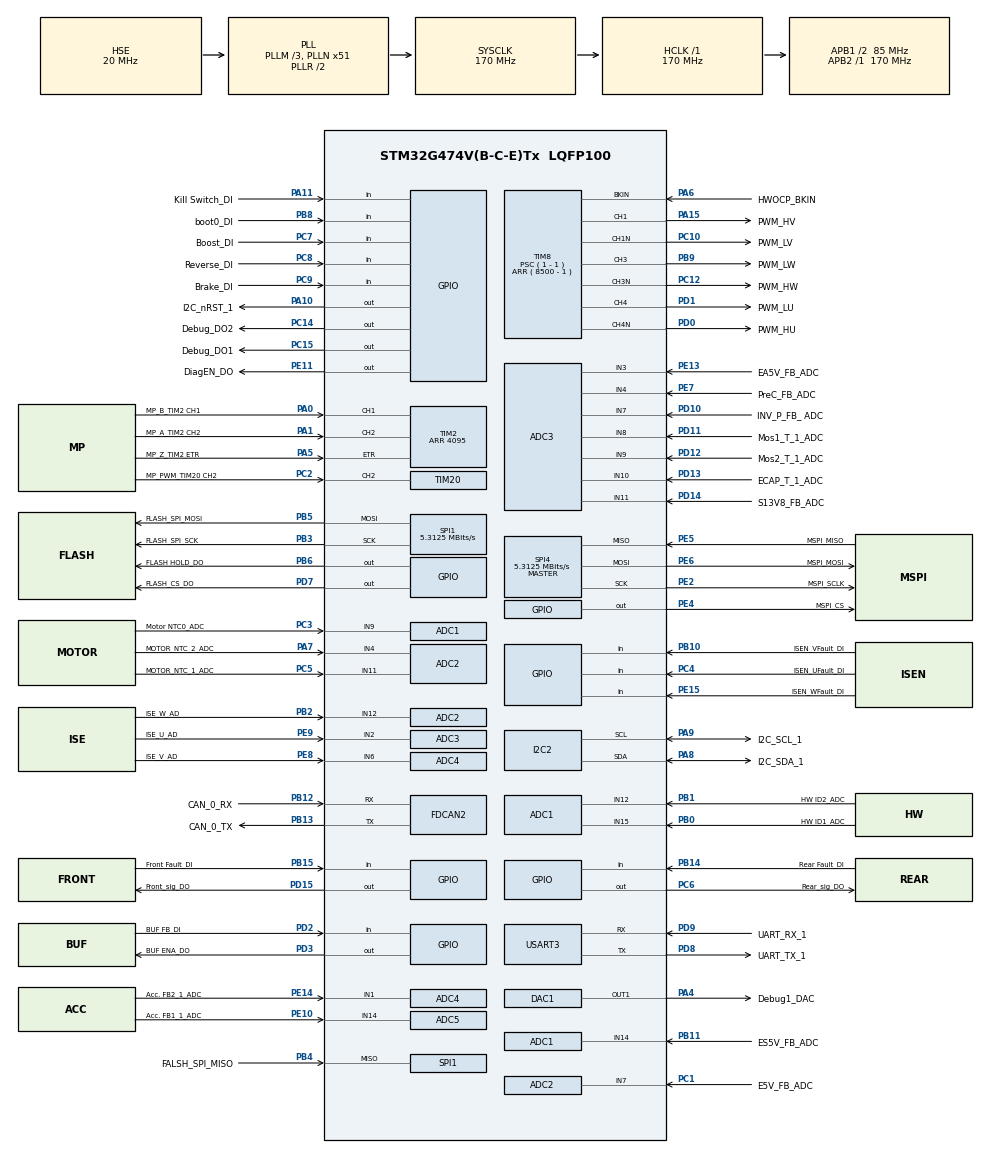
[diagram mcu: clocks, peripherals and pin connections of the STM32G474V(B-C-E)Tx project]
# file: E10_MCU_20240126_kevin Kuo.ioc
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ADC1.Channel-1\#ChannelRegularConversion=ADC_CHANNEL_9
ADC1.Channel-2\#ChannelRegularConversion=ADC_CHANNEL_14
ADC1.Channel-3\#ChannelRegularConversion=ADC_CHANNEL_15
ADC1.Channel-4\#ChannelRegularConversion=ADC_CHANNEL_12
ADC1.ClockPrescaler=ADC_CLOCK_ASYNC_DIV4
ADC1.DMAContinuousRequests=ENABLE
ADC1.EOCSelection=ADC_EOC_SEQ_CONV
ADC1.ExternalTrigConv=ADC_EXTERNALTRIG_T6_TRGO
ADC1.NbrOfConversion=4
ADC1.NbrOfConversionFlag=1
ADC1.OffsetNumber-1\#ChannelRegularConversion=ADC_OFFSET_NONE
ADC1.OffsetNumber-2\#ChannelRegularConversion=ADC_OFFSET_NONE
ADC1.OffsetNumber-3\#ChannelRegularConversion=ADC_OFFSET_NONE
ADC1.OffsetNumber-4\#ChannelRegularConversion=ADC_OFFSET_NONE
ADC1.Rank-1\#ChannelRegularConversion=1
ADC1.Rank-2\#ChannelRegularConversion=2
ADC1.Rank-3\#ChannelRegularConversion=3
ADC1.Rank-4\#ChannelRegularConversion=4
ADC1.SamplingTime-1\#ChannelRegularConversion=ADC_SAMPLETIME_47CYCLES_5
ADC1.SamplingTime-2\#ChannelRegularConversion=ADC_SAMPLETIME_47CYCLES_5
ADC1.SamplingTime-3\#ChannelRegularConversion=ADC_SAMPLETIME_47CYCLES_5
ADC1.SamplingTime-4\#ChannelRegularConversion=ADC_SAMPLETIME_47CYCLES_5
ADC1.master=1
ADC2.Channel-0\#ChannelRegularConversion=ADC_CHANNEL_7
ADC2.Channel-3\#ChannelRegularConversion=ADC_CHANNEL_11
ADC2.Channel-4\#ChannelRegularConversion=ADC_CHANNEL_4
ADC2.ClockPrescaler=ADC_CLOCK_ASYNC_DIV4
ADC2.DMAContinuousRequests=ENABLE
ADC2.EOCSelection=ADC_EOC_SEQ_CONV
ADC2.EnableInjectedConversion=ENABLE
ADC2.ExternalTrigConv=ADC_EXTERNALTRIG_T6_TRGO
ADC2.ExternalTrigInjecConv=ADC_EXTERNALTRIGINJEC_T8_TRGO
ADC2.InjNumberOfConversion=1
ADC2.InjectedChannel-2\#ChannelInjectedConversion=ADC_CHANNEL_12
ADC2.InjectedOffsetNumber-2\#ChannelInjectedConversion=ADC_OFFSET_NONE
ADC2.InjectedRank-2\#ChannelInjectedConversion=1
ADC2.InjectedSamplingTime-2\#ChannelInjectedConversion=ADC_SAMPLETIME_12CYCLES_5
ADC2.NbrOfConversion=3
ADC2.NbrOfConversionFlag=1
ADC2.OffsetNumber-0\#ChannelRegularConversion=ADC_OFFSET_NONE
ADC2.OffsetNumber-3\#ChannelRegularConversion=ADC_OFFSET_NONE
ADC2.OffsetNumber-4\#ChannelRegularConversion=ADC_OFFSET_NONE
ADC2.Rank-0\#ChannelRegularConversion=1
ADC2.Rank-3\#ChannelRegularConversion=2
ADC2.Rank-4\#ChannelRegularConversion=3
ADC2.SamplingTime-0\#ChannelRegularConversion=ADC_SAMPLETIME_92CYCLES_5
ADC2.SamplingTime-3\#ChannelRegularConversion=ADC_SAMPLETIME_92CYCLES_5
ADC2.SamplingTime-4\#ChannelRegularConversion=ADC_SAMPLETIME_92CYCLES_5
ADC3.Channel-0\#ChannelRegularConversion=ADC_CHANNEL_10
ADC3.Channel-1\#ChannelRegularConversion=ADC_CHANNEL_8
ADC3.Channel-2\#ChannelRegularConversion=ADC_CHANNEL_9
ADC3.Channel-3\#ChannelRegularConversion=ADC_CHANNEL_4
ADC3.Channel-4\#ChannelRegularConversion=ADC_CHANNEL_11
ADC3.Channel-5\#ChannelRegularConversion=ADC_CHANNEL_3
ADC3.ClockPrescaler=ADC_CLOCK_ASYNC_DIV4
ADC3.DMAContinuousRequests=ENABLE
ADC3.EOCSelection=ADC_EOC_SEQ_CONV
ADC3.EnableInjectedConversion=ENABLE
ADC3.ExternalTrigConv=ADC_EXTERNALTRIG_T6_TRGO
ADC3.ExternalTrigInjecConv=ADC_EXTERNALTRIGINJEC_T8_TRGO
ADC3.InjNumberOfConversion=2
ADC3.InjectedChannel-6\#ChannelInjectedConversion=ADC_CHANNEL_2
ADC3.InjectedChannel-7\#ChannelInjectedConversion=ADC_CHANNEL_7
ADC3.InjectedOffsetNumber-6\#ChannelInjectedConversion=ADC_OFFSET_NONE
ADC3.InjectedOffsetNumber-7\#ChannelInjectedConversion=ADC_OFFSET_NONE
ADC3.InjectedRank-6\#ChannelInjectedConversion=1
ADC3.InjectedRank-7\#ChannelInjectedConversion=2
ADC3.InjectedSamplingTime-6\#ChannelInjectedConversion=ADC_SAMPLETIME_12CYCLES_5
ADC3.InjectedSamplingTime-7\#ChannelInjectedConversion=ADC_SAMPLETIME_12CYCLES_5
ADC3.NbrOfConversion=6
ADC3.NbrOfConversionFlag=1
ADC3.OffsetNumber-0\#ChannelRegularConversion=ADC_OFFSET_NONE
ADC3.OffsetNumber-1\#ChannelRegularConversion=ADC_OFFSET_NONE
ADC3.OffsetNumber-2\#ChannelRegularConversion=ADC_OFFSET_NONE
ADC3.OffsetNumber-3\#ChannelRegularConversion=ADC_OFFSET_NONE
ADC3.OffsetNumber-4\#ChannelRegularConversion=ADC_OFFSET_NONE
ADC3.OffsetNumber-5\#ChannelRegularConversion=ADC_OFFSET_NONE
ADC3.Rank-0\#ChannelRegularConversion=1
ADC3.Rank-1\#ChannelRegularConversion=2
ADC3.Rank-2\#ChannelRegularConversion=3
ADC3.Rank-3\#ChannelRegularConversion=4
ADC3.Rank-4\#ChannelRegularConversion=5
ADC3.Rank-5\#ChannelRegularConversion=6
ADC3.Rank1_Channel=ADC_CHANNEL_2
ADC3.Rank2_Channel=ADC_CHANNEL_7
ADC3.SamplingTime-0\#ChannelRegularConversion=ADC_SAMPLETIME_47CYCLES_5
ADC3.SamplingTime-1\#ChannelRegularConversion=ADC_SAMPLETIME_47CYCLES_5
ADC3.SamplingTime-2\#ChannelRegularConversion=ADC_SAMPLETIME_47CYCLES_5
ADC3.SamplingTime-3\#ChannelRegularConversion=ADC_SAMPLETIME_47CYCLES_5
ADC3.SamplingTime-4\#ChannelRegularConversion=ADC_SAMPLETIME_47CYCLES_5
ADC3.SamplingTime-5\#ChannelRegularConversion=ADC_SAMPLETIME_47CYCLES_5
ADC3.master=1
ADC4.Channel-0\#ChannelRegularConversion=ADC_CHANNEL_1
ADC4.ClockPrescaler=ADC_CLOCK_ASYNC_DIV4
ADC4.DMAContinuousRequests=ENABLE
ADC4.EOCSelection=ADC_EOC_SEQ_CONV
ADC4.EnableInjectedConversion=ENABLE
ADC4.ExternalTrigConv=ADC_EXTERNALTRIG_T6_TRGO
ADC4.ExternalTrigInjecConv=ADC_EXTERNALTRIGINJEC_T8_TRGO
ADC4.InjNumberOfConversion=1
ADC4.InjectedChannel-2\#ChannelInjectedConversion=ADC_CHANNEL_6
ADC4.InjectedOffsetNumber-2\#ChannelInjectedConversion=ADC_OFFSET_NONE
ADC4.InjectedRank-2\#ChannelInjectedConversion=1
ADC4.InjectedSamplingTime-2\#ChannelInjectedConversion=ADC_SAMPLETIME_12CYCLES_5
ADC4.NbrOfConversion=1
ADC4.NbrOfConversionFlag=1
ADC4.OffsetNumber-0\#ChannelRegularConversion=ADC_OFFSET_NONE
ADC4.Rank-0\#ChannelRegularConversion=1
ADC4.Rank1_Channel=ADC_CHANNEL_6
ADC4.SamplingTime-0\#ChannelRegularConversion=ADC_SAMPLETIME_247CYCLES_5
ADC5.Channel-0\#ChannelRegularConversion=ADC_CHANNEL_14
ADC5.ClockPrescaler=ADC_CLOCK_ASYNC_DIV4
ADC5.DMAContinuousRequests=ENABLE
ADC5.EOCSelection=ADC_EOC_SEQ_CONV
ADC5.ExternalTrigConv=ADC_EXTERNALTRIG_T6_TRGO
ADC5.NbrOfConversionFlag=1
ADC5.OffsetNumber-0\#ChannelRegularConversion=ADC_OFFSET_NONE
ADC5.Rank-0\#ChannelRegularConversion=1
ADC5.SamplingTime-0\#ChannelRegularConversion=ADC_SAMPLETIME_247CYCLES_5
CRC.CRCLength=CRC_POLYLENGTH_16B
CRC.DefaultInitValueUse=DEFAULT_INIT_VALUE_DISABLE
CRC.DefaultPolynomialUse=DEFAULT_POLYNOMIAL_DISABLE
CRC.GeneratingPolynomial=X12+X5+X0
CRC.InitValue=0x0000
CRC.InputDataInversionMode=CRC_INPUTDATA_INVERSION_BYTE
CRC.OutputDataInversionMode=CRC_OUTPUTDATA_INVERSION_ENABLE
DAC1.DAC_SampleAndHold-DAC_OUT1=DAC_SAMPLEANDHOLD_DISABLE
Dma.ADC1.4.Direction=DMA_PERIPH_TO_MEMORY
Dma.ADC1.4.EventEnable=DISABLE
Dma.ADC1.4.Instance=DMA1_Channel1
Dma.ADC1.4.MemDataAlignment=DMA_MDATAALIGN_HALFWORD
Dma.ADC1.4.MemInc=DMA_MINC_ENABLE
Dma.ADC1.4.Mode=DMA_CIRCULAR
Dma.ADC1.4.PeriphDataAlignment=DMA_PDATAALIGN_HALFWORD
Dma.ADC1.4.PeriphInc=DMA_PINC_DISABLE
Dma.ADC1.4.Polarity=HAL_DMAMUX_REQ_GEN_RISING
Dma.ADC1.4.Priority=DMA_PRIORITY_LOW
Dma.ADC1.4.RequestNumber=1
Dma.ADC1.4.SignalID=NONE
Dma.ADC1.4.SyncEnable=DISABLE
Dma.ADC1.4.SyncPolarity=HAL_DMAMUX_SYNC_NO_EVENT
Dma.ADC1.4.SyncRequestNumber=1
Dma.ADC1.4.SyncSignalID=NONE
Dma.ADC2.3.Direction=DMA_PERIPH_TO_MEMORY
Dma.ADC2.3.EventEnable=DISABLE
Dma.ADC2.3.Instance=DMA1_Channel2
Dma.ADC2.3.MemDataAlignment=DMA_MDATAALIGN_HALFWORD
Dma.ADC2.3.MemInc=DMA_MINC_ENABLE
Dma.ADC2.3.Mode=DMA_CIRCULAR
Dma.ADC2.3.PeriphDataAlignment=DMA_PDATAALIGN_HALFWORD
Dma.ADC2.3.PeriphInc=DMA_PINC_DISABLE
Dma.ADC2.3.Polarity=HAL_DMAMUX_REQ_GEN_RISING
Dma.ADC2.3.Priority=DMA_PRIORITY_MEDIUM
Dma.ADC2.3.RequestNumber=1
Dma.ADC2.3.SignalID=NONE
Dma.ADC2.3.SyncEnable=DISABLE
Dma.ADC2.3.SyncPolarity=HAL_DMAMUX_SYNC_NO_EVENT
Dma.ADC2.3.SyncRequestNumber=1
Dma.ADC2.3.SyncSignalID=NONE
Dma.ADC3.2.Direction=DMA_PERIPH_TO_MEMORY
Dma.ADC3.2.EventEnable=DISABLE
Dma.ADC3.2.Instance=DMA1_Channel3
Dma.ADC3.2.MemDataAlignment=DMA_MDATAALIGN_HALFWORD
Dma.ADC3.2.MemInc=DMA_MINC_ENABLE
Dma.ADC3.2.Mode=DMA_CIRCULAR
Dma.ADC3.2.PeriphDataAlignment=DMA_PDATAALIGN_HALFWORD
Dma.ADC3.2.PeriphInc=DMA_PINC_DISABLE
Dma.ADC3.2.Polarity=HAL_DMAMUX_REQ_GEN_RISING
Dma.ADC3.2.Priority=DMA_PRIORITY_MEDIUM
Dma.ADC3.2.RequestNumber=1
Dma.ADC3.2.SignalID=NONE
Dma.ADC3.2.SyncEnable=DISABLE
Dma.ADC3.2.SyncPolarity=HAL_DMAMUX_SYNC_NO_EVENT
Dma.ADC3.2.SyncRequestNumber=1
Dma.ADC3.2.SyncSignalID=NONE
Dma.ADC4.1.Direction=DMA_PERIPH_TO_MEMORY
Dma.ADC4.1.EventEnable=DISABLE
Dma.ADC4.1.Instance=DMA1_Channel4
Dma.ADC4.1.MemDataAlignment=DMA_MDATAALIGN_HALFWORD
Dma.ADC4.1.MemInc=DMA_MINC_ENABLE
Dma.ADC4.1.Mode=DMA_CIRCULAR
Dma.ADC4.1.PeriphDataAlignment=DMA_PDATAALIGN_HALFWORD
Dma.ADC4.1.PeriphInc=DMA_PINC_DISABLE
Dma.ADC4.1.Polarity=HAL_DMAMUX_REQ_GEN_RISING
Dma.ADC4.1.Priority=DMA_PRIORITY_HIGH
Dma.ADC4.1.RequestNumber=1
Dma.ADC4.1.SignalID=NONE
Dma.ADC4.1.SyncEnable=DISABLE
Dma.ADC4.1.SyncPolarity=HAL_DMAMUX_SYNC_NO_EVENT
Dma.ADC4.1.SyncRequestNumber=1
Dma.ADC4.1.SyncSignalID=NONE
Dma.ADC5.0.Direction=DMA_PERIPH_TO_MEMORY
Dma.ADC5.0.EventEnable=DISABLE
Dma.ADC5.0.Instance=DMA1_Channel5
Dma.ADC5.0.MemDataAlignment=DMA_MDATAALIGN_HALFWORD
Dma.ADC5.0.MemInc=DMA_MINC_ENABLE
Dma.ADC5.0.Mode=DMA_CIRCULAR
Dma.ADC5.0.PeriphDataAlignment=DMA_PDATAALIGN_HALFWORD
Dma.ADC5.0.PeriphInc=DMA_PINC_DISABLE
Dma.ADC5.0.Polarity=HAL_DMAMUX_REQ_GEN_RISING
Dma.ADC5.0.Priority=DMA_PRIORITY_HIGH
Dma.ADC5.0.RequestNumber=1
Dma.ADC5.0.SignalID=NONE
Dma.ADC5.0.SyncEnable=DISABLE
Dma.ADC5.0.SyncPolarity=HAL_DMAMUX_SYNC_NO_EVENT
Dma.ADC5.0.SyncRequestNumber=1
Dma.ADC5.0.SyncSignalID=NONE
Dma.Request0=ADC5
Dma.Request1=ADC4
Dma.Request2=ADC3
Dma.Request3=ADC2
Dma.Request4=ADC1
FDCAN2.CalculateBaudRateNominal=499999
FDCAN2.CalculateTimeBitNominal=2000
FDCAN2.CalculateTimeQuantumNominal=58.82352941176471
FDCAN2.DataPrescaler=5
FDCAN2.DataSyncJumpWidth=6
FDCAN2.DataTimeSeg1=25
FDCAN2.DataTimeSeg2=8
FDCAN2.ExtFiltersNbr=4
FDCAN2.NominalPrescaler=5
FDCAN2.NominalSyncJumpWidth=6
FDCAN2.NominalTimeSeg1=25
FDCAN2.NominalTimeSeg2=8
FDCAN2.StdFiltersNbr=4
FDCAN2.TransmitPause=ENABLE
I2C2.CustomTiming=Disabled
I2C2.I2C_Coeff_DF=1
I2C2.I2C_Fall_Time=100
I2C2.I2C_Rise_Time=100
I2C2.Timing=0x20916FA0
Mcu.Family=STM32G4
Mcu.Name=STM32G474V(B-C-E)Tx
Mcu.Package=LQFP100
NVIC.ADC1_2_IRQn=true\:2\:0\:true\:false\:true\:true\:true\:true
NVIC.ADC3_IRQn=true\:2\:0\:true\:false\:true\:true\:true\:true
NVIC.ADC4_IRQn=true\:2\:0\:true\:false\:true\:true\:true\:true
NVIC.DMA1_Channel1_IRQn=true\:4\:0\:true\:false\:true\:false\:true\:true
NVIC.DMA1_Channel2_IRQn=true\:4\:0\:true\:false\:true\:false\:true\:true
NVIC.DMA1_Channel3_IRQn=true\:4\:0\:true\:false\:true\:false\:true\:true
NVIC.DMA1_Channel4_IRQn=true\:4\:0\:true\:false\:true\:false\:true\:true
NVIC.DMA1_Channel5_IRQn=true\:4\:0\:true\:false\:true\:false\:true\:true
NVIC.FDCAN2_IT0_IRQn=true\:8\:0\:true\:false\:true\:true\:true\:true
NVIC.FDCAN2_IT1_IRQn=true\:8\:0\:true\:false\:true\:true\:true\:true
NVIC.PriorityGroup=NVIC_PRIORITYGROUP_4
NVIC.TIM20_CC_IRQn=true\:0\:0\:false\:false\:true\:true\:true\:true
NVIC.TIM3_IRQn=true\:10\:0\:true\:false\:true\:true\:true\:true
NVIC.TIM7_DAC_IRQn=true\:6\:0\:true\:false\:true\:true\:true\:true
NVIC.TIM8_BRK_IRQn=true\:0\:0\:false\:false\:true\:true\:true\:true
NVIC.TIM8_UP_IRQn=true\:1\:0\:true\:false\:true\:true\:true\:true
PA0.GPIO_Label=MP_B_TIM2 CH1
PA0.Signal=S_TIM2_CH1
PA1.GPIO_Label=MP_A_TIM2 CH2
PA1.Signal=S_TIM2_CH2
PA10.GPIO_Label=I2C_nRST_1
PA10.Signal=GPIO_Output
PA11.GPIO_Label=Kill Switch_DI
PA11.Signal=GPIO_Input
PA13.Mode=Serial_Wire
PA13.Signal=SYS_JTMS-SWDIO
PA14.Mode=Serial_Wire
PA14.Signal=SYS_JTCK-SWCLK
PA15.GPIO_Label=PWM_HV
PA15.Signal=S_TIM8_CH1
PA4.GPIO_Label=Debug1_DAC
PA4.Signal=COMP_DAC11_group
PA5.GPIO_Label=MP_Z_TIM2 ETR
PA5.Signal=S_TIM2_ETR
PA6.GPIO_Label=HWOCP_BKIN
PA6.Mode=Activate-Break-Input
PA6.Signal=TIM8_BKIN
PA7.GPIO_Label=MOTOR_NTC_2_ADC
PA7.Mode=IN4-Single-Ended
PA7.Signal=ADC2_IN4
PA8.GPIO_Label=I2C_SDA_1
PA8.Mode=I2C
PA8.Signal=I2C2_SDA
PA9.GPIO_Label=I2C_SCL_1
PA9.Mode=I2C
PA9.Signal=I2C2_SCL
PB0.GPIO_Label=HW ID1_ADC
PB0.Mode=IN15-Single-Ended
PB0.Signal=ADC1_IN15
PB1.GPIO_Label=HW ID2_ADC
PB1.Mode=IN12-Single-Ended
PB1.Signal=ADC1_IN12
PB10.GPIO_Label=ISEN_VFault_DI
PB10.Signal=GPIO_Input
PB11.GPIO_Label=ES5V_FB_ADC
PB11.Mode=IN14-Single-Ended
PB11.Signal=ADC1_IN14
PB12.GPIO_Label=CAN_0_RX
PB12.Mode=FDCAN_Activate
PB12.Signal=FDCAN2_RX
PB13.GPIO_Label=CAN_0_TX
PB13.Mode=FDCAN_Activate
PB13.Signal=FDCAN2_TX
PB14.GPIO_Label=Rear Fault_DI
PB14.Signal=GPIO_Input
PB15.GPIO_Label=Front Fault_DI
PB15.Signal=GPIO_Input
PB2.GPIO_Label=ISE_W_AD
PB2.Mode=IN12-Single-Ended
PB2.Signal=ADC2_IN12
PB3.GPIO_Label=FLASH_SPI_SCK
PB3.Mode=Full_Duplex_Master
PB3.Signal=SPI1_SCK
PB4.GPIO_Label=FALSH_SPI_MISO
PB4.Mode=Full_Duplex_Master
PB4.Signal=SPI1_MISO
PB5.GPIO_Label=FLASH_SPI_MOSI
PB5.Mode=Full_Duplex_Master
PB5.Signal=SPI1_MOSI
PB6.GPIO_Label=FLASH HOLD_DO
PB6.Signal=GPIO_Output
PB8-BOOT0.GPIO_Label=boot0_DI
PB8-BOOT0.Signal=GPIO_Input
PB9.GPIO_Label=PWM_LW
PB9.Signal=S_TIM8_CH3
PC1.GPIO_Label=E5V_FB_ADC
PC1.Mode=IN7-Single-Ended
PC1.Signal=ADC2_IN7
PC10.GPIO_Label=PWM_LV
PC10.Mode=PWM Generation1 CH1 CH1N
PC10.Signal=TIM8_CH1N
PC12.GPIO_Label=PWM_HW
PC12.Mode=PWM Generation3 CH3 CH3N
PC12.Signal=TIM8_CH3N
PC14-OSC32_IN.GPIO_Label=Debug_DO2
PC14-OSC32_IN.Signal=GPIO_Output
PC15-OSC32_OUT.GPIO_Label=Debug_DO1
PC15-OSC32_OUT.Signal=GPIO_Output
PC2.GPIO_Label=MP_PWM_TIM20 CH2
PC2.Signal=S_TIM20_CH2
PC3.GPIO_Label=Motor NTC0_ADC
PC3.Mode=IN9-Single-Ended
PC3.Signal=ADC1_IN9
PC4.GPIO_Label=ISEN_UFault_DI
PC4.Signal=GPIO_Input
PC5.GPIO_Label=MOTOR_NTC_1_ADC
PC5.Mode=IN11-Single-Ended
PC5.Signal=ADC2_IN11
PC6.GPIO_Label=Rear_sig_DO
PC6.Signal=GPIO_Output
PC7.GPIO_Label=Boost_DI
PC7.Signal=GPIO_Input
PC8.GPIO_Label=Reverse_DI
PC8.Signal=GPIO_Input
PC9.GPIO_Label=Brake_DI
PC9.Signal=GPIO_Input
PD0.GPIO_Label=PWM_HU
PD0.Mode=PWM Generation4 CH4 CH4N
PD0.Signal=TIM8_CH4N
PD1.GPIO_Label=PWM_LU
PD1.Signal=S_TIM8_CH4
PD10.GPIO_Label=INV_P_FB_ ADC
PD10.Mode=IN7-Single-Ended
PD10.Signal=ADC3_IN7
PD11.GPIO_Label=Mos1_T_1_ADC
PD11.Mode=IN8-Single-Ended
PD11.Signal=ADC3_IN8
PD12.GPIO_Label=Mos2_T_1_ADC
PD12.Mode=IN9-Single-Ended
PD12.Signal=ADC3_IN9
PD13.GPIO_Label=ECAP_T_1_ADC
PD13.Mode=IN10-Single-Ended
PD13.Signal=ADC3_IN10
PD14.GPIO_Label=S13V8_FB_ADC
PD14.Mode=IN11-Single-Ended
PD14.Signal=ADC3_IN11
PD15.GPIO_Label=Front_sig_DO
PD15.Signal=GPIO_Output
PD2.GPIO_Label=BUF FB_DI
PD2.Signal=GPIO_Input
PD3.GPIO_Label=BUF ENA_DO
PD3.PinState=GPIO_PIN_SET
PD3.Signal=GPIO_Output
PD7.GPIO_Label=FLASH_CS_DO
PD7.Signal=GPIO_Output
PD8.GPIO_Label=UART_TX_1
PD8.Mode=Asynchronous
PD8.Signal=USART3_TX
PD9.GPIO_Label=UART_RX_1
PD9.Mode=Asynchronous
PD9.Signal=USART3_RX
PE10.GPIO_Label=Acc. FB1_1_ADC
PE10.Mode=IN14-Single-Ended
PE10.Signal=ADC5_IN14
PE11.GPIO_Label=DiagEN_DO
PE11.Signal=GPIO_Output
PE13.GPIO_Label=EA5V_FB_ADC
PE13.Mode=IN3-Single-Ended
PE13.Signal=ADC3_IN3
PE14.GPIO_Label=Acc. FB2_1_ADC
PE14.Mode=IN1-Single-Ended
PE14.Signal=ADC4_IN1
PE15.GPIO_Label=ISEN_WFault_DI
PE15.Signal=GPIO_Input
PE2.GPIO_Label=MSPI_SCLK
PE2.Mode=Full_Duplex_Master
PE2.Signal=SPI4_SCK
PE4.GPIO_Label=MSPI_CS
PE4.Signal=GPIO_Output
PE5.GPIO_Label=MSPI_MISO
PE5.Mode=Full_Duplex_Master
PE5.Signal=SPI4_MISO
PE6.GPIO_Label=MSPI_MOSI
PE6.Mode=Full_Duplex_Master
PE6.Signal=SPI4_MOSI
PE7.GPIO_Label=PreC_FB_ADC
PE7.Mode=IN4-Single-Ended
PE7.Signal=ADC3_IN4
PE8.GPIO_Label=ISE_V_AD
PE8.Mode=IN6-Single-Ended
PE8.Signal=ADC4_IN6
PE9.GPIO_Label=ISE_U_AD
PE9.Mode=IN2-Single-Ended
PE9.Signal=ADC3_IN2
PF0-OSC_IN.Mode=HSE-External-Oscillator
PF0-OSC_IN.Signal=RCC_OSC_IN
PF1-OSC_OUT.Mode=HSE-External-Oscillator
PF1-OSC_OUT.Signal=RCC_OSC_OUT
ProjectManager.HeapSize=0x100
ProjectManager.StackSize=0x400
ProjectManager.TargetToolchain=STM32CubeIDE
RCC.ADC12Freq_Value=170000000
RCC.ADC345Freq_Value=170000000
RCC.AHBFreq_Value=170000000
RCC.APB1CLKDivider=RCC_HCLK_DIV2
RCC.APB1Freq_Value=85000000
RCC.APB1TimFreq_Value=170000000
RCC.APB2Freq_Value=170000000
RCC.APB2TimFreq_Value=170000000
RCC.CortexFreq_Value=170000000
RCC.EXTERNAL_CLOCK_VALUE=12288000
RCC.HCLKFreq_Value=170000000
RCC.HSE_VALUE=20000000
RCC.HSI48_VALUE=48000000
RCC.HSI_VALUE=16000000
RCC.LSE_VALUE=32768
RCC.PLLM=RCC_PLLM_DIV3
RCC.PLLN=51
RCC.PLLSourceVirtual=RCC_PLLSOURCE_HSE
RCC.PWR_Regulator_Voltage_Scale=PWR_REGULATOR_VOLTAGE_SCALE1_BOOST
RCC.SYSCLKFreq_VALUE=170000000
RCC.SYSCLKSource=RCC_SYSCLKSOURCE_PLLCLK
RCC.USBFreq_Value=170000000
RCC.VCOOutputFreq_Value=340000000
SH.COMP_DAC11_group.0=DAC1_OUT1,DAC_OUT1
SH.S_TIM20_CH2.0=TIM20_CH2,PWM_Input_2
SH.S_TIM2_CH1.0=TIM2_CH1,Encoder_Interface_w_index
SH.S_TIM2_CH2.0=TIM2_CH2,Encoder_Interface_w_index
SH.S_TIM2_ETR.0=TIM2_ETR,Encoder_Interface_w_index
SH.S_TIM8_CH1.0=TIM8_CH1,PWM Generation1 CH1 CH1N
SH.S_TIM8_CH3.0=TIM8_CH3,PWM Generation3 CH3 CH3N
SH.S_TIM8_CH4.0=TIM8_CH4,PWM Generation4 CH4 CH4N
SPI1.BaudRatePrescaler=SPI_BAUDRATEPRESCALER_32
SPI1.CalculateBaudRate=5.3125 MBits/s
SPI1.DataSize=SPI_DATASIZE_8BIT
SPI1.Direction=SPI_DIRECTION_2LINES
SPI1.Mode=SPI_MODE_MASTER
SPI1.NSSPMode=SPI_NSS_PULSE_DISABLE
SPI1.VirtualType=VM_MASTER
SPI4.BaudRatePrescaler=SPI_BAUDRATEPRESCALER_32
SPI4.CLKPhase=SPI_PHASE_2EDGE
SPI4.CLKPolarity=SPI_POLARITY_HIGH
SPI4.CalculateBaudRate=5.3125 MBits/s
SPI4.DataSize=SPI_DATASIZE_16BIT
SPI4.Direction=SPI_DIRECTION_2LINES
SPI4.Mode=SPI_MODE_MASTER
SPI4.VirtualType=VM_MASTER
TIM2.EncoderMode=TIM_ENCODERMODE_TI12
TIM2.PeriodNoDither=4095
TIM20.ICPolarity_1=TIM_INPUTCHANNELPOLARITY_FALLING
TIM20.Prescaler=17-1
TIM3.PeriodNoDither=(15000-1)
TIM3.Prescaler=(34000 -1)
TIM3.TIM_MasterOutputTrigger=TIM_TRGO_RESET
TIM6.PeriodNoDither=(1000 - 1)
TIM6.Prescaler=(170 - 1)
TIM6.TIM_MasterOutputTrigger=TIM_TRGO_UPDATE
TIM7.PeriodNoDither=(10000-1)
TIM7.Prescaler=(170-1)
TIM7.TIM_MasterOutputTrigger=TIM_TRGO_UPDATE
TIM8.AutoReloadPreload=TIM_AUTORELOAD_PRELOAD_ENABLE
TIM8.BreakPolarity=TIM_BREAKPOLARITY_LOW
TIM8.Channel-PWM\ Generation1\ CH1\ CH1N=TIM_CHANNEL_1
TIM8.Channel-PWM\ Generation3\ CH3\ CH3N=TIM_CHANNEL_3
TIM8.Channel-PWM\ Generation4\ CH4\ CH4N=TIM_CHANNEL_4
TIM8.CounterMode=TIM_COUNTERMODE_CENTERALIGNED1
TIM8.DeadTime=128
TIM8.OCMode_PWM-PWM\ Generation1\ CH1\ CH1N=TIM_OCMODE_PWM2
TIM8.PeriodNoDither=( 8500 - 1 )
TIM8.Prescaler=( 1 - 1 )
TIM8.PulseNoDither_1=8500-1
TIM8.PulseNoDither_3=8500-1
TIM8.PulseNoDither_4=8500-1
TIM8.RepetitionCounter=1
TIM8.SourceBRKDigInput=TIM_BREAKINPUTSOURCE_ENABLE
TIM8.TIM_MasterOutputTrigger=TIM_TRGO_UPDATE
USART3.FIFOMode=FIFOMODE_ENABLE
USART3.VirtualMode-Asynchronous=VM_ASYNC
VP_CORDIC_VS_CORDIC.Mode=CORDIC_Activate
VP_CRC_VS_CRC.Mode=CRC_Activate
VP_SYS_VS_DBSignals.Mode=DisableDeadBatterySignals
VP_SYS_V_PVD_IN.Mode=Mode_PVD_Int
VP_TIM20_VS_ClockSourceINT.Mode=Internal
VP_TIM3_VS_ClockSourceINT.Mode=Internal
VP_TIM6_VS_ClockSourceINT.Mode=Enable_Timer
VP_TIM7_VS_ClockSourceINT.Mode=Enable_Timer
VP_TIM8_VS_ClockSourceINT.Mode=Internal
board=custom

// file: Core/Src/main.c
/* USER CODE BEGIN Header */
/**
  ******************************************************************************
  * @file           : main.c
  * @brief          : Main program body
  ******************************************************************************
  * @attention
  *
  * Copyright (c) 2024 STMicroelectronics.
  * All rights reserved.
  *
  * This software is licensed under terms that can be found in the LICENSE file
  * in the root directory of this software component.
  * If no LICENSE file comes with this software, it is provided AS-IS.
  *
  ******************************************************************************
  */
/* USER CODE END Header */
#include "main.h"

/* USER CODE BEGIN Includes */
#include "Drive.h"
/* USER CODE END Includes */

ADC_HandleTypeDef hadc1;
ADC_HandleTypeDef hadc2;
ADC_HandleTypeDef hadc3;
ADC_HandleTypeDef hadc4;
ADC_HandleTypeDef hadc5;
DMA_HandleTypeDef hdma_adc1;
DMA_HandleTypeDef hdma_adc2;
DMA_HandleTypeDef hdma_adc3;
DMA_HandleTypeDef hdma_adc4;
DMA_HandleTypeDef hdma_adc5;

CORDIC_HandleTypeDef hcordic;

CRC_HandleTypeDef hcrc;

DAC_HandleTypeDef hdac1;

FDCAN_HandleTypeDef hfdcan2;

I2C_HandleTypeDef hi2c2;

SPI_HandleTypeDef hspi1;
SPI_HandleTypeDef hspi4;
TIM_HandleTypeDef htim1;
TIM_HandleTypeDef htim2;
TIM_HandleTypeDef htim3;
TIM_HandleTypeDef htim6;
TIM_HandleTypeDef htim7;
TIM_HandleTypeDef htim8;
TIM_HandleTypeDef htim20;

UART_HandleTypeDef huart3;

void SystemClock_Config(void);
static void MX_GPIO_Init(void);
static void MX_DMA_Init(void);
static void MX_ADC1_Init(void);
static void MX_ADC2_Init(void);
static void MX_ADC3_Init(void);
static void MX_ADC4_Init(void);
static void MX_ADC5_Init(void);
static void MX_DAC1_Init(void);
static void MX_FDCAN2_Init(void);
static void MX_SPI1_Init(void);
static void MX_TIM8_Init(void);
static void MX_TIM6_Init(void);
static void MX_TIM3_Init(void);
static void MX_TIM2_Init(void);
static void MX_TIM20_Init(void);
static void MX_CORDIC_Init(void);
static void MX_USART3_UART_Init(void);
static void MX_TIM7_Init(void);
static void MX_CRC_Init(void);
static void MX_SPI4_Init(void);
static void MX_I2C2_Init(void);
/* USER CODE BEGIN PFP */
#if MEASURE_CPU_LOAD || JUDGE_FUNCTION_DELAY
static void USER_DWT_Init(void);
#endif
/* USER CODE END PFP */

int main(void)
{

  /* MCU Configuration--------------------------------------------------------*/

  /* Reset of all peripherals, Initializes the Flash interface and the Systick. */
  HAL_Init();

  /* Configure the system clock */
  SystemClock_Config();

  /* Initialize all configured peripherals */
  MX_GPIO_Init();
  MX_DMA_Init();
  MX_ADC1_Init();
  MX_ADC2_Init();
  MX_ADC3_Init();
  MX_ADC4_Init();
  MX_ADC5_Init();
  MX_DAC1_Init();
  MX_FDCAN2_Init();
  MX_SPI1_Init();
  MX_TIM8_Init();
  MX_TIM6_Init();
  MX_TIM3_Init();
  MX_TIM2_Init();
  MX_TIM20_Init();
  MX_CORDIC_Init();
  MX_USART3_UART_Init();
  MX_TIM7_Init();
  MX_CRC_Init();
  MX_SPI4_Init();
  MX_I2C2_Init();
  /************************************************/
  /*    Start encoder interface                   */
  /************************************************/
 // HAL_TIM_Encoder_Start(&htim2, TIM_CHANNEL_ALL);
  /* USER CODE BEGIN 2 */

  /*## Start the Input Capture in interrupt mode ##########################*/
  if (HAL_TIM_IC_Start_IT(&htim20, TIM_CHANNEL_2) != HAL_OK)
  {
    /* Starting Error */
    Error_Handler();
  }

  /*## Start the Input Capture in interrupt mode ##########################*/
  if (HAL_TIM_IC_Start_IT(&htim20, TIM_CHANNEL_1) != HAL_OK)
  {
    /* Starting Error */
    Error_Handler();
  }

  drive_Init();
  __disable_irq();
  HAL_TIM_Base_Start(&htim6);
  HAL_TIM_Base_Start_IT(&htim7);
  __HAL_FLASH_CLEAR_FLAG( FLASH_FLAG_ALL_ERRORS );
//  HAL_TIM_Base_Start(&htim16);
  __enable_irq();

#if MEASURE_CPU_LOAD || JUDGE_FUNCTION_DELAY
  USER_DWT_Init();
#endif

  /* USER CODE END 2 */

  /* Infinite loop */
  while (1)
  {

    /* USER CODE BEGIN 3 */
	  drive_DoHouseKeeping();
	  JumpCtrlFunction();
  }
  /* USER CODE END 3 */
}

void SystemClock_Config(void)
{
  RCC_OscInitTypeDef RCC_OscInitStruct = {0};
  RCC_ClkInitTypeDef RCC_ClkInitStruct = {0};
//  RCC_PeriphCLKInitTypeDef PeriphClkInit = {0};

  /** Configure the main internal regulator output voltage
  */
  HAL_PWREx_ControlVoltageScaling(PWR_REGULATOR_VOLTAGE_SCALE1_BOOST);

  /** Initializes the RCC Oscillators according to the specified parameters
  * in the RCC_OscInitTypeDef structure.
  */
  RCC_OscInitStruct.OscillatorType = RCC_OSCILLATORTYPE_HSE;
  RCC_OscInitStruct.HSEState = RCC_HSE_ON;
  RCC_OscInitStruct.PLL.PLLState = RCC_PLL_ON;
  RCC_OscInitStruct.PLL.PLLSource = RCC_PLLSOURCE_HSE;
  RCC_OscInitStruct.PLL.PLLM = RCC_PLLM_DIV3;
  RCC_OscInitStruct.PLL.PLLN = 51;
  RCC_OscInitStruct.PLL.PLLP = RCC_PLLP_DIV2;
  RCC_OscInitStruct.PLL.PLLQ = RCC_PLLQ_DIV2;
  RCC_OscInitStruct.PLL.PLLR = RCC_PLLR_DIV2;
  if (HAL_RCC_OscConfig(&RCC_OscInitStruct) != HAL_OK)
  {
    Error_Handler();
  }

  /** Initializes the CPU, AHB and APB buses clocks
  */
  RCC_ClkInitStruct.ClockType = RCC_CLOCKTYPE_HCLK|RCC_CLOCKTYPE_SYSCLK
                              |RCC_CLOCKTYPE_PCLK1|RCC_CLOCKTYPE_PCLK2;
  RCC_ClkInitStruct.SYSCLKSource = RCC_SYSCLKSOURCE_PLLCLK;
  RCC_ClkInitStruct.AHBCLKDivider = RCC_SYSCLK_DIV1;
  RCC_ClkInitStruct.APB1CLKDivider = RCC_HCLK_DIV2;
  RCC_ClkInitStruct.APB2CLKDivider = RCC_HCLK_DIV1;

  if (HAL_RCC_ClockConfig(&RCC_ClkInitStruct, FLASH_LATENCY_4) != HAL_OK) // newX: 8 -> E10: 4
  {
    Error_Handler();
  }
   /* check the following is necessary?
  PeriphClkInit.PeriphClockSelection = RCC_PERIPHCLK_USART2|RCC_PERIPHCLK_UART5
                              |RCC_PERIPHCLK_ADC12|RCC_PERIPHCLK_ADC345
                              |RCC_PERIPHCLK_FDCAN;
  PeriphClkInit.Usart2ClockSelection = RCC_USART2CLKSOURCE_PCLK1;
  PeriphClkInit.Uart5ClockSelection = RCC_UART5CLKSOURCE_PCLK1;
  PeriphClkInit.FdcanClockSelection = RCC_FDCANCLKSOURCE_PCLK1;
  PeriphClkInit.Adc12ClockSelection = RCC_ADC12CLKSOURCE_SYSCLK;
  PeriphClkInit.Adc345ClockSelection = RCC_ADC345CLKSOURCE_SYSCLK;
  if (HAL_RCCEx_PeriphCLKConfig(&PeriphClkInit) != HAL_OK)
  {
    Error_Handler();
  }
  */
}

static void MX_ADC1_Init(void)
{

  ADC_MultiModeTypeDef multimode = {0};
  ADC_ChannelConfTypeDef sConfig = {0};

  /** Common config
  */
  hadc1.Instance = ADC1;
  hadc1.Init.ClockPrescaler = ADC_CLOCK_ASYNC_DIV4;
  hadc1.Init.Resolution = ADC_RESOLUTION_12B;
  hadc1.Init.DataAlign = ADC_DATAALIGN_RIGHT;
  hadc1.Init.GainCompensation = 0;
  hadc1.Init.ScanConvMode = ADC_SCAN_ENABLE;
  hadc1.Init.EOCSelection = ADC_EOC_SEQ_CONV;
  hadc1.Init.LowPowerAutoWait = DISABLE;
  hadc1.Init.ContinuousConvMode = DISABLE;
  hadc1.Init.NbrOfConversion = 4;
  hadc1.Init.DiscontinuousConvMode = DISABLE;
  hadc1.Init.ExternalTrigConv = ADC_EXTERNALTRIG_T6_TRGO;
  hadc1.Init.ExternalTrigConvEdge = ADC_EXTERNALTRIGCONVEDGE_RISING;
  hadc1.Init.DMAContinuousRequests = ENABLE;
  hadc1.Init.Overrun = ADC_OVR_DATA_PRESERVED;
  hadc1.Init.OversamplingMode = DISABLE;
  if (HAL_ADC_Init(&hadc1) != HAL_OK)
  {
    Error_Handler();
  }

  /** Configure the ADC multi-mode
  */
  multimode.Mode = ADC_MODE_INDEPENDENT;
  if (HAL_ADCEx_MultiModeConfigChannel(&hadc1, &multimode) != HAL_OK)
  {
    Error_Handler();
  }

  /** Configure Regular Channel
  */
  sConfig.Channel = ADC_CHANNEL_9;
  sConfig.Rank = ADC_REGULAR_RANK_1;
  sConfig.SamplingTime = ADC_SAMPLETIME_47CYCLES_5;
  sConfig.SingleDiff = ADC_SINGLE_ENDED;
  sConfig.OffsetNumber = ADC_OFFSET_NONE;
  sConfig.Offset = 0;
  if (HAL_ADC_ConfigChannel(&hadc1, &sConfig) != HAL_OK)
  {
    Error_Handler();
  }

  /** Configure Regular Channel
  */
  sConfig.Channel = ADC_CHANNEL_14;
  sConfig.Rank = ADC_REGULAR_RANK_2;
  if (HAL_ADC_ConfigChannel(&hadc1, &sConfig) != HAL_OK)
  {
    Error_Handler();
  }

  /** Configure Regular Channel
  */
  sConfig.Channel = ADC_CHANNEL_15;
  sConfig.Rank = ADC_REGULAR_RANK_3;
  if (HAL_ADC_ConfigChannel(&hadc1, &sConfig) != HAL_OK)
  {
    Error_Handler();
  }

  /** Configure Regular Channel
  */
  sConfig.Channel = ADC_CHANNEL_12;
  sConfig.Rank = ADC_REGULAR_RANK_4;
  if (HAL_ADC_ConfigChannel(&hadc1, &sConfig) != HAL_OK)
  {
    Error_Handler();
  }

}

static void MX_ADC2_Init(void)
{

  ADC_ChannelConfTypeDef sConfig = {0};
  ADC_InjectionConfTypeDef sConfigInjected = {0};

  /** Common config
  */
  hadc2.Instance = ADC2;
  hadc2.Init.ClockPrescaler = ADC_CLOCK_ASYNC_DIV4;
  hadc2.Init.Resolution = ADC_RESOLUTION_12B;
  hadc2.Init.DataAlign = ADC_DATAALIGN_RIGHT;
  hadc2.Init.GainCompensation = 0;
  hadc2.Init.ScanConvMode = ADC_SCAN_ENABLE;
  hadc2.Init.EOCSelection = ADC_EOC_SEQ_CONV;
  hadc2.Init.LowPowerAutoWait = DISABLE;
  hadc2.Init.ContinuousConvMode = DISABLE;
  hadc2.Init.NbrOfConversion = 3;
  hadc2.Init.DiscontinuousConvMode = DISABLE;
  hadc2.Init.ExternalTrigConv = ADC_EXTERNALTRIG_T6_TRGO;
  hadc2.Init.ExternalTrigConvEdge = ADC_EXTERNALTRIGCONVEDGE_RISING;
  hadc2.Init.DMAContinuousRequests = ENABLE;
  hadc2.Init.Overrun = ADC_OVR_DATA_PRESERVED;
  hadc2.Init.OversamplingMode = DISABLE;
  if (HAL_ADC_Init(&hadc2) != HAL_OK)
  {
    Error_Handler();
  }

  /** Configure Regular Channel
  */
  sConfig.Channel = ADC_CHANNEL_7;
  sConfig.Rank = ADC_REGULAR_RANK_1;
  sConfig.SamplingTime = ADC_SAMPLETIME_247CYCLES_5;
  sConfig.SingleDiff = ADC_SINGLE_ENDED;
  sConfig.OffsetNumber = ADC_OFFSET_NONE;
  sConfig.Offset = 0;
  if (HAL_ADC_ConfigChannel(&hadc2, &sConfig) != HAL_OK)
  {
    Error_Handler();
  }

  /** Configure Regular Channel
  */
  sConfig.Channel = ADC_CHANNEL_11;
  sConfig.Rank = ADC_REGULAR_RANK_2;
  sConfig.SamplingTime = ADC_SAMPLETIME_47CYCLES_5;
  if (HAL_ADC_ConfigChannel(&hadc2, &sConfig) != HAL_OK)
  {
    Error_Handler();
  }

  /** Configure Regular Channel
  */
  sConfig.Channel = ADC_CHANNEL_4;
  sConfig.Rank = ADC_REGULAR_RANK_3;
  if (HAL_ADC_ConfigChannel(&hadc2, &sConfig) != HAL_OK)
  {
    Error_Handler();
  }

  /** Configure Injected Channel
  */
  sConfigInjected.InjectedChannel = ADC_CHANNEL_12;
  sConfigInjected.InjectedRank = ADC_INJECTED_RANK_1;
  sConfigInjected.InjectedSamplingTime = ADC_SAMPLETIME_12CYCLES_5;
  sConfigInjected.InjectedSingleDiff = ADC_SINGLE_ENDED;
  sConfigInjected.InjectedOffsetNumber = ADC_OFFSET_NONE;
  sConfigInjected.InjectedOffset = 0;
  sConfigInjected.InjectedNbrOfConversion = 1;
  sConfigInjected.InjectedDiscontinuousConvMode = DISABLE;
  sConfigInjected.AutoInjectedConv = DISABLE;
  sConfigInjected.QueueInjectedContext = DISABLE;
  sConfigInjected.ExternalTrigInjecConv = ADC_EXTERNALTRIGINJEC_T8_TRGO;
  sConfigInjected.ExternalTrigInjecConvEdge = ADC_EXTERNALTRIGINJECCONV_EDGE_RISING;
  sConfigInjected.InjecOversamplingMode = DISABLE;
  if (HAL_ADCEx_InjectedConfigChannel(&hadc2, &sConfigInjected) != HAL_OK)
  {
    Error_Handler();
  }

}

static void MX_ADC3_Init(void)
{

  ADC_MultiModeTypeDef multimode = {0};
  ADC_ChannelConfTypeDef sConfig = {0};
  ADC_InjectionConfTypeDef sConfigInjected = {0};

  /** Common config
  */
  hadc3.Instance = ADC3;
  hadc3.Init.ClockPrescaler = ADC_CLOCK_ASYNC_DIV4;
  hadc3.Init.Resolution = ADC_RESOLUTION_12B;
  hadc3.Init.DataAlign = ADC_DATAALIGN_RIGHT;
  hadc3.Init.GainCompensation = 0;
  hadc3.Init.ScanConvMode = ADC_SCAN_ENABLE;
  hadc3.Init.EOCSelection = ADC_EOC_SEQ_CONV;
  hadc3.Init.LowPowerAutoWait = DISABLE;
  hadc3.Init.ContinuousConvMode = DISABLE;
  hadc3.Init.NbrOfConversion = 6;
  hadc3.Init.DiscontinuousConvMode = DISABLE;
  hadc3.Init.ExternalTrigConv = ADC_EXTERNALTRIG_T6_TRGO;
  hadc3.Init.ExternalTrigConvEdge = ADC_EXTERNALTRIGCONVEDGE_RISING;
  hadc3.Init.DMAContinuousRequests = ENABLE;
  hadc3.Init.Overrun = ADC_OVR_DATA_PRESERVED;
  hadc3.Init.OversamplingMode = DISABLE;
  if (HAL_ADC_Init(&hadc3) != HAL_OK)
  {
    Error_Handler();
  }

  /** Configure the ADC multi-mode
  */
  multimode.Mode = ADC_MODE_INDEPENDENT;
  if (HAL_ADCEx_MultiModeConfigChannel(&hadc3, &multimode) != HAL_OK)
  {
    Error_Handler();
  }

  /** Configure Regular Channel
  */
  sConfig.Channel = ADC_CHANNEL_10;
  sConfig.Rank = ADC_REGULAR_RANK_1;
  sConfig.SamplingTime = ADC_SAMPLETIME_47CYCLES_5;
  sConfig.SingleDiff = ADC_SINGLE_ENDED;
  sConfig.OffsetNumber = ADC_OFFSET_NONE;
  sConfig.Offset = 0;
  if (HAL_ADC_ConfigChannel(&hadc3, &sConfig) != HAL_OK)
  {
    Error_Handler();
  }

  /** Configure Regular Channel
  */
  sConfig.Channel = ADC_CHANNEL_8;
  sConfig.Rank = ADC_REGULAR_RANK_2;
  if (HAL_ADC_ConfigChannel(&hadc3, &sConfig) != HAL_OK)
  {
    Error_Handler();
  }

  /** Configure Regular Channel
  */
  sConfig.Channel = ADC_CHANNEL_9;
  sConfig.Rank = ADC_REGULAR_RANK_3;
  if (HAL_ADC_ConfigChannel(&hadc3, &sConfig) != HAL_OK)
  {
    Error_Handler();
  }

  /** Configure Regular Channel
  */
  sConfig.Channel = ADC_CHANNEL_4;
  sConfig.Rank = ADC_REGULAR_RANK_4;
  if (HAL_ADC_ConfigChannel(&hadc3, &sConfig) != HAL_OK)
  {
    Error_Handler();
  }

  /** Configure Regular Channel
  */
  sConfig.Channel = ADC_CHANNEL_11;
  sConfig.Rank = ADC_REGULAR_RANK_5;
  if (HAL_ADC_ConfigChannel(&hadc3, &sConfig) != HAL_OK)
  {
    Error_Handler();
  }

  /** Configure Regular Channel
  */
  sConfig.Channel = ADC_CHANNEL_3;
  sConfig.Rank = ADC_REGULAR_RANK_6;
  if (HAL_ADC_ConfigChannel(&hadc3, &sConfig) != HAL_OK)
  {
    Error_Handler();
  }

  /** Configure Injected Channel
  */
  sConfigInjected.InjectedChannel = ADC_CHANNEL_2;
  sConfigInjected.InjectedRank = ADC_INJECTED_RANK_1;
  sConfigInjected.InjectedSamplingTime = ADC_SAMPLETIME_12CYCLES_5;
  sConfigInjected.InjectedSingleDiff = ADC_SINGLE_ENDED;
  sConfigInjected.InjectedOffsetNumber = ADC_OFFSET_NONE;
  sConfigInjected.InjectedOffset = 0;
  sConfigInjected.InjectedNbrOfConversion = 2;
  sConfigInjected.InjectedDiscontinuousConvMode = DISABLE;
  sConfigInjected.AutoInjectedConv = DISABLE;
  sConfigInjected.QueueInjectedContext = DISABLE;
  sConfigInjected.ExternalTrigInjecConv = ADC_EXTERNALTRIGINJEC_T8_TRGO;
  sConfigInjected.ExternalTrigInjecConvEdge = ADC_EXTERNALTRIGINJECCONV_EDGE_RISING;
  sConfigInjected.InjecOversamplingMode = DISABLE;
  if (HAL_ADCEx_InjectedConfigChannel(&hadc3, &sConfigInjected) != HAL_OK)
  {
    Error_Handler();
  }

  /** Configure Injected Channel
  */
  sConfigInjected.InjectedChannel = ADC_CHANNEL_7;
  sConfigInjected.InjectedRank = ADC_INJECTED_RANK_2;
  if (HAL_ADCEx_InjectedConfigChannel(&hadc3, &sConfigInjected) != HAL_OK)
  {
    Error_Handler();
  }

}

static void MX_ADC4_Init(void)
{

  ADC_ChannelConfTypeDef sConfig = {0};
  ADC_InjectionConfTypeDef sConfigInjected = {0};

  /** Common config
  */
  hadc4.Instance = ADC4;
  hadc4.Init.ClockPrescaler = ADC_CLOCK_ASYNC_DIV4;
  hadc4.Init.Resolution = ADC_RESOLUTION_12B;
  hadc4.Init.DataAlign = ADC_DATAALIGN_RIGHT;
  hadc4.Init.GainCompensation = 0;
  hadc4.Init.ScanConvMode = ADC_SCAN_DISABLE;
  hadc4.Init.EOCSelection = ADC_EOC_SEQ_CONV;
  hadc4.Init.LowPowerAutoWait = DISABLE;
  hadc4.Init.ContinuousConvMode = DISABLE;
  hadc4.Init.NbrOfConversion = 1;
  hadc4.Init.DiscontinuousConvMode = DISABLE;
  hadc4.Init.ExternalTrigConv = ADC_EXTERNALTRIG_T6_TRGO;
  hadc4.Init.ExternalTrigConvEdge = ADC_EXTERNALTRIGCONVEDGE_RISING;
  hadc4.Init.DMAContinuousRequests = ENABLE;
  hadc4.Init.Overrun = ADC_OVR_DATA_PRESERVED;
  hadc4.Init.OversamplingMode = DISABLE;
  if (HAL_ADC_Init(&hadc4) != HAL_OK)
  {
    Error_Handler();
  }

  /** Configure Regular Channel
  */
  sConfig.Channel = ADC_CHANNEL_1;
  sConfig.Rank = ADC_REGULAR_RANK_1;
  sConfig.SamplingTime = ADC_SAMPLETIME_247CYCLES_5;
  sConfig.SingleDiff = ADC_SINGLE_ENDED;
  sConfig.OffsetNumber = ADC_OFFSET_NONE;
  sConfig.Offset = 0;
  if (HAL_ADC_ConfigChannel(&hadc4, &sConfig) != HAL_OK)
  {
    Error_Handler();
  }

  /** Configure Injected Channel
  */
  sConfigInjected.InjectedChannel = ADC_CHANNEL_6;
  sConfigInjected.InjectedRank = ADC_INJECTED_RANK_1;
  sConfigInjected.InjectedSamplingTime = ADC_SAMPLETIME_12CYCLES_5;
  sConfigInjected.InjectedSingleDiff = ADC_SINGLE_ENDED;
  sConfigInjected.InjectedOffsetNumber = ADC_OFFSET_NONE;
  sConfigInjected.InjectedOffset = 0;
  sConfigInjected.InjectedNbrOfConversion = 1;
  sConfigInjected.InjectedDiscontinuousConvMode = DISABLE;
  sConfigInjected.AutoInjectedConv = DISABLE;
  sConfigInjected.QueueInjectedContext = DISABLE;
  sConfigInjected.ExternalTrigInjecConv = ADC_EXTERNALTRIGINJEC_T8_TRGO;
  sConfigInjected.ExternalTrigInjecConvEdge = ADC_EXTERNALTRIGINJECCONV_EDGE_RISING;
  sConfigInjected.InjecOversamplingMode = DISABLE;
  if (HAL_ADCEx_InjectedConfigChannel(&hadc4, &sConfigInjected) != HAL_OK)
  {
    Error_Handler();
  }

}

static void MX_ADC5_Init(void)
{

  ADC_ChannelConfTypeDef sConfig = {0};

  /** Common config
  */
  hadc5.Instance = ADC5;
  hadc5.Init.ClockPrescaler = ADC_CLOCK_ASYNC_DIV4;
  hadc5.Init.Resolution = ADC_RESOLUTION_12B;
  hadc5.Init.DataAlign = ADC_DATAALIGN_RIGHT;
  hadc5.Init.GainCompensation = 0;
  hadc5.Init.ScanConvMode = ADC_SCAN_DISABLE;
  hadc5.Init.EOCSelection = ADC_EOC_SEQ_CONV;
  hadc5.Init.LowPowerAutoWait = DISABLE;
  hadc5.Init.ContinuousConvMode = DISABLE;
  hadc5.Init.NbrOfConversion = 1;
  hadc5.Init.DiscontinuousConvMode = DISABLE;
  hadc5.Init.ExternalTrigConv = ADC_EXTERNALTRIG_T6_TRGO;
  hadc5.Init.ExternalTrigConvEdge = ADC_EXTERNALTRIGCONVEDGE_RISING;
  hadc5.Init.DMAContinuousRequests = ENABLE;
  hadc5.Init.Overrun = ADC_OVR_DATA_PRESERVED;
  hadc5.Init.OversamplingMode = DISABLE;
  if (HAL_ADC_Init(&hadc5) != HAL_OK)
  {
    Error_Handler();
  }

  /** Configure Regular Channel
  */
  sConfig.Channel = ADC_CHANNEL_14;
  sConfig.Rank = ADC_REGULAR_RANK_1;
  sConfig.SamplingTime = ADC_SAMPLETIME_247CYCLES_5;
  sConfig.SingleDiff = ADC_SINGLE_ENDED;
  sConfig.OffsetNumber = ADC_OFFSET_NONE;
  sConfig.Offset = 0;
  if (HAL_ADC_ConfigChannel(&hadc5, &sConfig) != HAL_OK)
  {
    Error_Handler();
  }

}

static void MX_CORDIC_Init(void)
{

  hcordic.Instance = CORDIC;
  if (HAL_CORDIC_Init(&hcordic) != HAL_OK)
  {
    Error_Handler();
  }

}

static void MX_CRC_Init(void)
{

  hcrc.Instance = CRC;
  hcrc.Init.DefaultPolynomialUse = DEFAULT_POLYNOMIAL_DISABLE;
  hcrc.Init.DefaultInitValueUse = DEFAULT_INIT_VALUE_DISABLE;
  hcrc.Init.GeneratingPolynomial = 4129;
  hcrc.Init.CRCLength = CRC_POLYLENGTH_16B;
  hcrc.Init.InitValue = 0x0000;
  hcrc.Init.InputDataInversionMode = CRC_INPUTDATA_INVERSION_BYTE;
  hcrc.Init.OutputDataInversionMode = CRC_OUTPUTDATA_INVERSION_ENABLE;
  hcrc.InputDataFormat = CRC_INPUTDATA_FORMAT_BYTES;
  if (HAL_CRC_Init(&hcrc) != HAL_OK)
  {
    Error_Handler();
  }

}

static void MX_DAC1_Init(void)
{

  DAC_ChannelConfTypeDef sConfig = {0};

  /** DAC Initialization
  */
  hdac1.Instance = DAC1;
  if (HAL_DAC_Init(&hdac1) != HAL_OK)
  {
    Error_Handler();
  }

  /** DAC channel OUT1 config
  */
  sConfig.DAC_HighFrequency = DAC_HIGH_FREQUENCY_INTERFACE_MODE_AUTOMATIC;
  sConfig.DAC_DMADoubleDataMode = DISABLE;
  sConfig.DAC_SignedFormat = DISABLE;
  sConfig.DAC_SampleAndHold = DAC_SAMPLEANDHOLD_DISABLE;
  sConfig.DAC_Trigger = DAC_TRIGGER_NONE;
  sConfig.DAC_Trigger2 = DAC_TRIGGER_NONE;
  sConfig.DAC_OutputBuffer = DAC_OUTPUTBUFFER_ENABLE;
  sConfig.DAC_ConnectOnChipPeripheral = DAC_CHIPCONNECT_EXTERNAL;
  sConfig.DAC_UserTrimming = DAC_TRIMMING_FACTORY;
  if (HAL_DAC_ConfigChannel(&hdac1, &sConfig, DAC_CHANNEL_1) != HAL_OK)
  {
    Error_Handler();
  }

}

static void MX_FDCAN2_Init(void)
{

  hfdcan2.Instance = FDCAN2;
  hfdcan2.Init.ClockDivider = FDCAN_CLOCK_DIV1;
  hfdcan2.Init.FrameFormat = FDCAN_FRAME_CLASSIC;
  hfdcan2.Init.Mode = FDCAN_MODE_NORMAL;
  hfdcan2.Init.AutoRetransmission = DISABLE;
  hfdcan2.Init.TransmitPause = ENABLE;
  hfdcan2.Init.ProtocolException = DISABLE;
  hfdcan2.Init.NominalPrescaler = 5;
  hfdcan2.Init.NominalSyncJumpWidth = 6;
  hfdcan2.Init.NominalTimeSeg1 = 25;
  hfdcan2.Init.NominalTimeSeg2 = 8;
  hfdcan2.Init.DataPrescaler = 5;
  hfdcan2.Init.DataSyncJumpWidth = 6;
  hfdcan2.Init.DataTimeSeg1 = 25;
  hfdcan2.Init.DataTimeSeg2 = 8;
  hfdcan2.Init.StdFiltersNbr = 4;
  hfdcan2.Init.ExtFiltersNbr = 4;
  hfdcan2.Init.TxFifoQueueMode = FDCAN_TX_FIFO_OPERATION;
  if (HAL_FDCAN_Init(&hfdcan2) != HAL_OK)
  {
    Error_Handler();
  }

}

static void MX_I2C2_Init(void)
{

  hi2c2.Instance = I2C2;
  hi2c2.Init.Timing = 0x20916FA0;
  hi2c2.Init.OwnAddress1 = 0;
  hi2c2.Init.AddressingMode = I2C_ADDRESSINGMODE_7BIT;
  hi2c2.Init.DualAddressMode = I2C_DUALADDRESS_DISABLE;
  hi2c2.Init.OwnAddress2 = 0;
  hi2c2.Init.OwnAddress2Masks = I2C_OA2_NOMASK;
  hi2c2.Init.GeneralCallMode = I2C_GENERALCALL_DISABLE;
  hi2c2.Init.NoStretchMode = I2C_NOSTRETCH_DISABLE;
  if (HAL_I2C_Init(&hi2c2) != HAL_OK)
  {
    Error_Handler();
  }

  /** Configure Analogue filter
  */
  if (HAL_I2CEx_ConfigAnalogFilter(&hi2c2, I2C_ANALOGFILTER_ENABLE) != HAL_OK)
  {
    Error_Handler();
  }

  /** Configure Digital filter
  */
  if (HAL_I2CEx_ConfigDigitalFilter(&hi2c2, 1) != HAL_OK)
  {
    Error_Handler();
  }

}

static void MX_SPI1_Init(void)
{

  /* SPI1 parameter configuration*/
  hspi1.Instance = SPI1;
  hspi1.Init.Mode = SPI_MODE_MASTER;
  hspi1.Init.Direction = SPI_DIRECTION_2LINES;
  hspi1.Init.DataSize = SPI_DATASIZE_8BIT;
  hspi1.Init.CLKPolarity = SPI_POLARITY_LOW;
  hspi1.Init.CLKPhase = SPI_PHASE_1EDGE;
  hspi1.Init.NSS = SPI_NSS_SOFT;
  hspi1.Init.BaudRatePrescaler = SPI_BAUDRATEPRESCALER_32;
  hspi1.Init.FirstBit = SPI_FIRSTBIT_MSB;
  hspi1.Init.TIMode = SPI_TIMODE_DISABLE;
  hspi1.Init.CRCCalculation = SPI_CRCCALCULATION_DISABLE;
  hspi1.Init.CRCPolynomial = 7;
  hspi1.Init.CRCLength = SPI_CRC_LENGTH_DATASIZE;
  hspi1.Init.NSSPMode = SPI_NSS_PULSE_DISABLE;
  if (HAL_SPI_Init(&hspi1) != HAL_OK)
  {
    Error_Handler();
  }

}

static void MX_SPI4_Init(void)
{

  /* SPI4 parameter configuration*/
  hspi4.Instance = SPI4;
  hspi4.Init.Mode = SPI_MODE_MASTER;
  hspi4.Init.Direction = SPI_DIRECTION_2LINES;
  hspi4.Init.DataSize = SPI_DATASIZE_16BIT;
  hspi4.Init.CLKPolarity = SPI_POLARITY_HIGH;
  hspi4.Init.CLKPhase = SPI_PHASE_2EDGE;
  hspi4.Init.NSS = SPI_NSS_SOFT;
  hspi4.Init.BaudRatePrescaler = SPI_BAUDRATEPRESCALER_32;
  hspi4.Init.FirstBit = SPI_FIRSTBIT_MSB;
  hspi4.Init.TIMode = SPI_TIMODE_DISABLE;
  hspi4.Init.CRCCalculation = SPI_CRCCALCULATION_DISABLE;
  hspi4.Init.CRCPolynomial = 7;
  hspi4.Init.CRCLength = SPI_CRC_LENGTH_DATASIZE;
  hspi4.Init.NSSPMode = SPI_NSS_PULSE_DISABLE;
  if (HAL_SPI_Init(&hspi4) != HAL_OK)
  {
    Error_Handler();
  }

}

static void MX_TIM2_Init(void)
{

  TIM_Encoder_InitTypeDef sConfig = {0};
  TIM_MasterConfigTypeDef sMasterConfig = {0};
  TIMEx_EncoderIndexConfigTypeDef sEncoderIndexConfig = {0};

  htim2.Instance = TIM2;
  htim2.Init.Prescaler = 0;
  htim2.Init.CounterMode = TIM_COUNTERMODE_UP;
  htim2.Init.Period = 262143; // 2^18 -1
  htim2.Init.ClockDivision = TIM_CLOCKDIVISION_DIV1;
  htim2.Init.AutoReloadPreload = TIM_AUTORELOAD_PRELOAD_DISABLE;
  sConfig.EncoderMode = TIM_ENCODERMODE_TI12;
  sConfig.IC1Polarity = TIM_ICPOLARITY_RISING;
  sConfig.IC1Selection = TIM_ICSELECTION_DIRECTTI;
  sConfig.IC1Prescaler = TIM_ICPSC_DIV1;
  sConfig.IC1Filter = 0;
  sConfig.IC2Polarity = TIM_ICPOLARITY_RISING;
  sConfig.IC2Selection = TIM_ICSELECTION_DIRECTTI;
  sConfig.IC2Prescaler = TIM_ICPSC_DIV1;
  sConfig.IC2Filter = 0;
  if (HAL_TIM_Encoder_Init(&htim2, &sConfig) != HAL_OK)
  {
    Error_Handler();
  }
  sMasterConfig.MasterOutputTrigger = TIM_TRGO_RESET;
  sMasterConfig.MasterSlaveMode = TIM_MASTERSLAVEMODE_DISABLE;
  if (HAL_TIMEx_MasterConfigSynchronization(&htim2, &sMasterConfig) != HAL_OK)
  {
    Error_Handler();
  }
  sEncoderIndexConfig.Polarity = TIM_ENCODERINDEX_POLARITY_NONINVERTED;
  sEncoderIndexConfig.Prescaler = TIM_ENCODERINDEX_PRESCALER_DIV1;
  sEncoderIndexConfig.Filter = 0;
  sEncoderIndexConfig.FirstIndexEnable = DISABLE;
  sEncoderIndexConfig.Position = TIM_ENCODERINDEX_POSITION_00;
  sEncoderIndexConfig.Direction = TIM_ENCODERINDEX_DIRECTION_UP_DOWN;
  if (HAL_TIMEx_ConfigEncoderIndex(&htim2, &sEncoderIndexConfig) != HAL_OK)
  {
    Error_Handler();
  }

}

static void MX_TIM3_Init(void)
{

  TIM_ClockConfigTypeDef sClockSourceConfig = {0};
  TIM_MasterConfigTypeDef sMasterConfig = {0};

  htim3.Instance = TIM3;
  htim3.Init.Prescaler = (34000 -1);
  htim3.Init.CounterMode = TIM_COUNTERMODE_UP;
  htim3.Init.Period = 14999;
  htim3.Init.ClockDivision = TIM_CLOCKDIVISION_DIV1;
  htim3.Init.AutoReloadPreload = TIM_AUTORELOAD_PRELOAD_DISABLE;
  if (HAL_TIM_Base_Init(&htim3) != HAL_OK)
  {
    Error_Handler();
  }
  sClockSourceConfig.ClockSource = TIM_CLOCKSOURCE_INTERNAL;
  if (HAL_TIM_ConfigClockSource(&htim3, &sClockSourceConfig) != HAL_OK)
  {
    Error_Handler();
  }
  sMasterConfig.MasterOutputTrigger = TIM_TRGO_RESET;
  sMasterConfig.MasterSlaveMode = TIM_MASTERSLAVEMODE_DISABLE;
  if (HAL_TIMEx_MasterConfigSynchronization(&htim3, &sMasterConfig) != HAL_OK)
  {
    Error_Handler();
  }

}

static void MX_TIM6_Init(void)
{

  TIM_MasterConfigTypeDef sMasterConfig = {0};

  htim6.Instance = TIM6;
  htim6.Init.Prescaler = (170 - 1);
  htim6.Init.CounterMode = TIM_COUNTERMODE_UP;
  htim6.Init.Period = 999;
  htim6.Init.AutoReloadPreload = TIM_AUTORELOAD_PRELOAD_DISABLE;
  if (HAL_TIM_Base_Init(&htim6) != HAL_OK)
  {
    Error_Handler();
  }
  sMasterConfig.MasterOutputTrigger = TIM_TRGO_UPDATE;
  sMasterConfig.MasterSlaveMode = TIM_MASTERSLAVEMODE_DISABLE;
  if (HAL_TIMEx_MasterConfigSynchronization(&htim6, &sMasterConfig) != HAL_OK)
  {
    Error_Handler();
  }

}

static void MX_TIM7_Init(void)
{

  TIM_MasterConfigTypeDef sMasterConfig = {0};

  htim7.Instance = TIM7;
  htim7.Init.Prescaler = (170-1);
  htim7.Init.CounterMode = TIM_COUNTERMODE_UP;
  htim7.Init.Period = 9999;
  htim7.Init.AutoReloadPreload = TIM_AUTORELOAD_PRELOAD_DISABLE;
  if (HAL_TIM_Base_Init(&htim7) != HAL_OK)
  {
    Error_Handler();
  }
  sMasterConfig.MasterOutputTrigger = TIM_TRGO_UPDATE;
  sMasterConfig.MasterSlaveMode = TIM_MASTERSLAVEMODE_DISABLE;
  if (HAL_TIMEx_MasterConfigSynchronization(&htim7, &sMasterConfig) != HAL_OK)
  {
    Error_Handler();
  }

}

static void MX_TIM8_Init(void)
{

  TIM_ClockConfigTypeDef sClockSourceConfig = {0};
  TIM_MasterConfigTypeDef sMasterConfig = {0};
  TIMEx_BreakInputConfigTypeDef sBreakInputConfig = {0};
  TIM_OC_InitTypeDef sConfigOC = {0};
  TIM_BreakDeadTimeConfigTypeDef sBreakDeadTimeConfig = {0};

  htim8.Instance = TIM8;
  htim8.Init.Prescaler = ( 1 - 1 );
  htim8.Init.CounterMode = TIM_COUNTERMODE_CENTERALIGNED1;
  htim8.Init.Period = (8500 - 1);
  htim8.Init.ClockDivision = TIM_CLOCKDIVISION_DIV1;
  htim8.Init.RepetitionCounter = 1;
  htim8.Init.AutoReloadPreload = TIM_AUTORELOAD_PRELOAD_ENABLE;
  if (HAL_TIM_Base_Init(&htim8) != HAL_OK)
  {
    Error_Handler();
  }
  sClockSourceConfig.ClockSource = TIM_CLOCKSOURCE_INTERNAL;
  if (HAL_TIM_ConfigClockSource(&htim8, &sClockSourceConfig) != HAL_OK)
  {
    Error_Handler();
  }
  if (HAL_TIM_PWM_Init(&htim8) != HAL_OK)
  {
    Error_Handler();
  }
  sMasterConfig.MasterOutputTrigger = TIM_TRGO_UPDATE;
  sMasterConfig.MasterOutputTrigger2 = TIM_TRGO2_RESET;
  sMasterConfig.MasterSlaveMode = TIM_MASTERSLAVEMODE_DISABLE;
  if (HAL_TIMEx_MasterConfigSynchronization(&htim8, &sMasterConfig) != HAL_OK)
  {
    Error_Handler();
  }
  sBreakInputConfig.Source = TIM_BREAKINPUTSOURCE_BKIN;
  sBreakInputConfig.Enable = TIM_BREAKINPUTSOURCE_ENABLE;
  sBreakInputConfig.Polarity = TIM_BREAKINPUTSOURCE_POLARITY_LOW; // HWOCP pin is low active
  if (HAL_TIMEx_ConfigBreakInput(&htim8, TIM_BREAKINPUT_BRK, &sBreakInputConfig) != HAL_OK)
  {
    Error_Handler();
  }
  sConfigOC.OCMode = TIM_OCMODE_PWM2;
  sConfigOC.Pulse = 8501;
  sConfigOC.OCPolarity = TIM_OCPOLARITY_LOW; // low active
  sConfigOC.OCNPolarity = TIM_OCPOLARITY_LOW; // low active
  sConfigOC.OCFastMode = TIM_OCFAST_DISABLE;
  sConfigOC.OCIdleState = TIM_OCIDLESTATE_RESET;
  sConfigOC.OCNIdleState = TIM_OCNIDLESTATE_RESET;
  if (HAL_TIM_PWM_ConfigChannel(&htim8, &sConfigOC, TIM_CHANNEL_1) != HAL_OK)
  {
    Error_Handler();
  }
  sConfigOC.OCMode = TIM_OCMODE_PWM1;
  if (HAL_TIM_PWM_ConfigChannel(&htim8, &sConfigOC, TIM_CHANNEL_3) != HAL_OK)
  {
    Error_Handler();
  }
  if (HAL_TIM_PWM_ConfigChannel(&htim8, &sConfigOC, TIM_CHANNEL_4) != HAL_OK)
  {
    Error_Handler();
  }
  sBreakDeadTimeConfig.OffStateRunMode = TIM_OSSR_DISABLE;
  sBreakDeadTimeConfig.OffStateIDLEMode = TIM_OSSI_DISABLE;
  sBreakDeadTimeConfig.LockLevel = TIM_LOCKLEVEL_OFF;
  sBreakDeadTimeConfig.DeadTime = 203;
  sBreakDeadTimeConfig.BreakState = TIM_BREAK_DISABLE; // Avoid to detect HWOCAP when the OCP circuit is unstable.
  sBreakDeadTimeConfig.BreakPolarity = TIM_BREAKPOLARITY_HIGH; // overall polarity is high
  sBreakDeadTimeConfig.BreakFilter = 0;
  sBreakDeadTimeConfig.BreakAFMode = TIM_BREAK_AFMODE_INPUT;
  sBreakDeadTimeConfig.Break2State = TIM_BREAK2_DISABLE;
  sBreakDeadTimeConfig.Break2Polarity = TIM_BREAK2POLARITY_HIGH;
  sBreakDeadTimeConfig.Break2Filter = 0;
  sBreakDeadTimeConfig.Break2AFMode = TIM_BREAK_AFMODE_INPUT;
  sBreakDeadTimeConfig.AutomaticOutput = TIM_AUTOMATICOUTPUT_DISABLE;
  if (HAL_TIMEx_ConfigBreakDeadTime(&htim8, &sBreakDeadTimeConfig) != HAL_OK)
  {
    Error_Handler();
  }
  HAL_TIM_MspPostInit(&htim8);

}

static void MX_TIM20_Init(void)
{

  TIM_ClockConfigTypeDef sClockSourceConfig = {0};
  TIM_SlaveConfigTypeDef sSlaveConfig = {0};
  TIM_IC_InitTypeDef sConfigIC = {0};
  TIM_MasterConfigTypeDef sMasterConfig = {0};

  htim20.Instance = TIM20;
  htim20.Init.Prescaler = 17-1;
  htim20.Init.CounterMode = TIM_COUNTERMODE_UP;
  htim20.Init.Period = 65535;
  htim20.Init.ClockDivision = TIM_CLOCKDIVISION_DIV1;
  htim20.Init.RepetitionCounter = 0;
  htim20.Init.AutoReloadPreload = TIM_AUTORELOAD_PRELOAD_DISABLE;
  if (HAL_TIM_Base_Init(&htim20) != HAL_OK)
  {
    Error_Handler();
  }
  sClockSourceConfig.ClockSource = TIM_CLOCKSOURCE_INTERNAL;
  if (HAL_TIM_ConfigClockSource(&htim20, &sClockSourceConfig) != HAL_OK)
  {
    Error_Handler();
  }
  if (HAL_TIM_IC_Init(&htim20) != HAL_OK)
  {
    Error_Handler();
  }
  sSlaveConfig.SlaveMode = TIM_SLAVEMODE_RESET;
  sSlaveConfig.InputTrigger = TIM_TS_TI2FP2;
  sSlaveConfig.TriggerPolarity = TIM_INPUTCHANNELPOLARITY_RISING;
  sSlaveConfig.TriggerPrescaler = TIM_ICPSC_DIV1;
  sSlaveConfig.TriggerFilter = 0;
  if (HAL_TIM_SlaveConfigSynchro(&htim20, &sSlaveConfig) != HAL_OK)
  {
    Error_Handler();
  }
  sConfigIC.ICPolarity = TIM_INPUTCHANNELPOLARITY_FALLING;
  sConfigIC.ICSelection = TIM_ICSELECTION_INDIRECTTI;
  sConfigIC.ICPrescaler = TIM_ICPSC_DIV1;
  sConfigIC.ICFilter = 0;
  if (HAL_TIM_IC_ConfigChannel(&htim20, &sConfigIC, TIM_CHANNEL_1) != HAL_OK)
  {
    Error_Handler();
  }
  sConfigIC.ICPolarity = TIM_INPUTCHANNELPOLARITY_RISING;
  sConfigIC.ICSelection = TIM_ICSELECTION_DIRECTTI;
  if (HAL_TIM_IC_ConfigChannel(&htim20, &sConfigIC, TIM_CHANNEL_2) != HAL_OK)
  {
    Error_Handler();
  }
  sMasterConfig.MasterOutputTrigger = TIM_TRGO_RESET;
  sMasterConfig.MasterOutputTrigger2 = TIM_TRGO2_RESET;
  sMasterConfig.MasterSlaveMode = TIM_MASTERSLAVEMODE_DISABLE;
  if (HAL_TIMEx_MasterConfigSynchronization(&htim20, &sMasterConfig) != HAL_OK)
  {
    Error_Handler();
  }

}

static void MX_USART3_UART_Init(void)
{

  huart3.Instance = USART3;
  huart3.Init.BaudRate = 115200;
  huart3.Init.WordLength = UART_WORDLENGTH_8B;
  huart3.Init.StopBits = UART_STOPBITS_1;
  huart3.Init.Parity = UART_PARITY_NONE;
  huart3.Init.Mode = UART_MODE_TX_RX;
  huart3.Init.HwFlowCtl = UART_HWCONTROL_NONE;
  huart3.Init.OverSampling = UART_OVERSAMPLING_16;
  huart3.Init.OneBitSampling = UART_ONE_BIT_SAMPLE_DISABLE;
  huart3.Init.ClockPrescaler = UART_PRESCALER_DIV1;
  huart3.AdvancedInit.AdvFeatureInit = UART_ADVFEATURE_NO_INIT;
  if (HAL_UART_Init(&huart3) != HAL_OK)
  {
    Error_Handler();
  }
  if (HAL_UARTEx_SetTxFifoThreshold(&huart3, UART_TXFIFO_THRESHOLD_1_8) != HAL_OK)
  {
    Error_Handler();
  }
  if (HAL_UARTEx_SetRxFifoThreshold(&huart3, UART_RXFIFO_THRESHOLD_1_8) != HAL_OK)
  {
    Error_Handler();
  }
  if (HAL_UARTEx_EnableFifoMode(&huart3) != HAL_OK)
  {
    Error_Handler();
  }

}

static void MX_DMA_Init(void)
{

  /* DMA controller clock enable */
  __HAL_RCC_DMAMUX1_CLK_ENABLE();
  __HAL_RCC_DMA1_CLK_ENABLE();

  /* DMA interrupt init */
  /* DMA1_Channel1_IRQn interrupt configuration */
  HAL_NVIC_SetPriority(DMA1_Channel1_IRQn, 4, 0);
  HAL_NVIC_EnableIRQ(DMA1_Channel1_IRQn);
  /* DMA1_Channel2_IRQn interrupt configuration */
  HAL_NVIC_SetPriority(DMA1_Channel2_IRQn, 4, 0);
  HAL_NVIC_EnableIRQ(DMA1_Channel2_IRQn);
  /* DMA1_Channel3_IRQn interrupt configuration */
  HAL_NVIC_SetPriority(DMA1_Channel3_IRQn, 4, 0);
  HAL_NVIC_EnableIRQ(DMA1_Channel3_IRQn);
  /* DMA1_Channel4_IRQn interrupt configuration */
  HAL_NVIC_SetPriority(DMA1_Channel4_IRQn, 4, 0);
  HAL_NVIC_EnableIRQ(DMA1_Channel4_IRQn);
  /* DMA1_Channel5_IRQn interrupt configuration */
  HAL_NVIC_SetPriority(DMA1_Channel5_IRQn, 4, 0);
  HAL_NVIC_EnableIRQ(DMA1_Channel5_IRQn);

}

static void MX_GPIO_Init(void)
{
  GPIO_InitTypeDef GPIO_InitStruct = {0};

  /* GPIO Ports Clock Enable */
  __HAL_RCC_GPIOE_CLK_ENABLE();
  __HAL_RCC_GPIOC_CLK_ENABLE();
  __HAL_RCC_GPIOF_CLK_ENABLE();
  __HAL_RCC_GPIOG_CLK_ENABLE();
  __HAL_RCC_GPIOA_CLK_ENABLE();
  __HAL_RCC_GPIOB_CLK_ENABLE();
  __HAL_RCC_GPIOD_CLK_ENABLE();

  /*Configure GPIO pin Output Level */
  HAL_GPIO_WritePin(GPIOE, MSPI_CS_Pin|DiagEN_DO_Pin, GPIO_PIN_RESET);

  /*Configure GPIO pin Output Level */
  HAL_GPIO_WritePin(GPIOC, Debug_DO2_Pin|Debug_DO1_Pin|Rear_sig_DO_Pin, GPIO_PIN_RESET);

  /*Configure GPIO pin Output Level */
  HAL_GPIO_WritePin(GPIOD, Front_sig_DO_Pin|FLASH_CS_DO_Pin, GPIO_PIN_RESET);

  /*Configure GPIO pin Output Level */
  HAL_GPIO_WritePin(I2C_nRST_1_GPIO_Port, I2C_nRST_1_Pin, GPIO_PIN_RESET);

  /*Configure GPIO pin Output Level */
  HAL_GPIO_WritePin(BUF_ENA_DO_GPIO_Port, BUF_ENA_DO_Pin, GPIO_PIN_SET);

  /*Configure GPIO pin Output Level */
  HAL_GPIO_WritePin(FLASH_HOLD_DO_GPIO_Port, FLASH_HOLD_DO_Pin, GPIO_PIN_RESET);

  /*Configure GPIO pins : PE3 PE12 PE0 PE1 */
  GPIO_InitStruct.Pin = GPIO_PIN_3|GPIO_PIN_12|GPIO_PIN_0|GPIO_PIN_1;
  GPIO_InitStruct.Mode = GPIO_MODE_ANALOG;
  GPIO_InitStruct.Pull = GPIO_NOPULL;
  HAL_GPIO_Init(GPIOE, &GPIO_InitStruct);

  /*Configure GPIO pins : MSPI_CS_Pin DiagEN_DO_Pin */
  GPIO_InitStruct.Pin = MSPI_CS_Pin|DiagEN_DO_Pin;
  GPIO_InitStruct.Mode = GPIO_MODE_OUTPUT_PP;
  GPIO_InitStruct.Pull = GPIO_NOPULL;
  GPIO_InitStruct.Speed = GPIO_SPEED_FREQ_LOW;
  HAL_GPIO_Init(GPIOE, &GPIO_InitStruct);

  /*Configure GPIO pins : PC13 PC0 PC11 */
  GPIO_InitStruct.Pin = GPIO_PIN_13|GPIO_PIN_0|GPIO_PIN_11;
  GPIO_InitStruct.Mode = GPIO_MODE_ANALOG;
  GPIO_InitStruct.Pull = GPIO_NOPULL;
  HAL_GPIO_Init(GPIOC, &GPIO_InitStruct);

  /*Configure GPIO pins : Debug_DO2_Pin Debug_DO1_Pin Rear_sig_DO_Pin */
  GPIO_InitStruct.Pin = Debug_DO2_Pin|Debug_DO1_Pin|Rear_sig_DO_Pin;
  GPIO_InitStruct.Mode = GPIO_MODE_OUTPUT_PP;
  GPIO_InitStruct.Pull = GPIO_NOPULL;
  GPIO_InitStruct.Speed = GPIO_SPEED_FREQ_LOW;
  HAL_GPIO_Init(GPIOC, &GPIO_InitStruct);

  /*Configure GPIO pins : PF9 PF10 PF2 */
  GPIO_InitStruct.Pin = GPIO_PIN_9|GPIO_PIN_10|GPIO_PIN_2;
  GPIO_InitStruct.Mode = GPIO_MODE_ANALOG;
  GPIO_InitStruct.Pull = GPIO_NOPULL;
  HAL_GPIO_Init(GPIOF, &GPIO_InitStruct);

  /*Configure GPIO pin : PG10 */
  GPIO_InitStruct.Pin = GPIO_PIN_10;
  GPIO_InitStruct.Mode = GPIO_MODE_ANALOG;
  GPIO_InitStruct.Pull = GPIO_NOPULL;
  HAL_GPIO_Init(GPIOG, &GPIO_InitStruct);

  /*Configure GPIO pins : PA2 PA3 PA12 */
  GPIO_InitStruct.Pin = GPIO_PIN_2|GPIO_PIN_3|GPIO_PIN_12;
  GPIO_InitStruct.Mode = GPIO_MODE_ANALOG;
  GPIO_InitStruct.Pull = GPIO_NOPULL;
  HAL_GPIO_Init(GPIOA, &GPIO_InitStruct);

  /*Configure GPIO pins : ISEN_UFault_DI_Pin Boost_DI_Pin Reverse_DI_Pin Brake_DI_Pin */
  GPIO_InitStruct.Pin = ISEN_UFault_DI_Pin|Boost_DI_Pin|Reverse_DI_Pin|Brake_DI_Pin;
  GPIO_InitStruct.Mode = GPIO_MODE_INPUT;
  GPIO_InitStruct.Pull = GPIO_NOPULL;
  HAL_GPIO_Init(GPIOC, &GPIO_InitStruct);

  /*Configure GPIO pin : ISEN_WFault_DI_Pin */
  GPIO_InitStruct.Pin = ISEN_WFault_DI_Pin;
  GPIO_InitStruct.Mode = GPIO_MODE_INPUT;
  GPIO_InitStruct.Pull = GPIO_NOPULL;
  HAL_GPIO_Init(ISEN_WFault_DI_GPIO_Port, &GPIO_InitStruct);

  /*Configure GPIO pins : ISEN_VFault_DI_Pin Rear_Fault_DI_Pin Front_Fault_DI_Pin boot0_DI_Pin */
  GPIO_InitStruct.Pin = ISEN_VFault_DI_Pin|Rear_Fault_DI_Pin|Front_Fault_DI_Pin|boot0_DI_Pin;
  GPIO_InitStruct.Mode = GPIO_MODE_INPUT;
  GPIO_InitStruct.Pull = GPIO_NOPULL;
  HAL_GPIO_Init(GPIOB, &GPIO_InitStruct);

  /*Configure GPIO pins : Front_sig_DO_Pin BUF_ENA_DO_Pin FLASH_CS_DO_Pin */
  GPIO_InitStruct.Pin = Front_sig_DO_Pin|BUF_ENA_DO_Pin|FLASH_CS_DO_Pin;
  GPIO_InitStruct.Mode = GPIO_MODE_OUTPUT_PP;
  GPIO_InitStruct.Pull = GPIO_NOPULL;
  GPIO_InitStruct.Speed = GPIO_SPEED_FREQ_LOW;
  HAL_GPIO_Init(GPIOD, &GPIO_InitStruct);

  /*Configure GPIO pin : I2C_nRST_1_Pin */
  GPIO_InitStruct.Pin = I2C_nRST_1_Pin;
  GPIO_InitStruct.Mode = GPIO_MODE_OUTPUT_PP;
  GPIO_InitStruct.Pull = GPIO_NOPULL;
  GPIO_InitStruct.Speed = GPIO_SPEED_FREQ_LOW;
  HAL_GPIO_Init(I2C_nRST_1_GPIO_Port, &GPIO_InitStruct);

  /*Configure GPIO pin : Kill_Switch_DI_Pin */
  GPIO_InitStruct.Pin = Kill_Switch_DI_Pin;
  GPIO_InitStruct.Mode = GPIO_MODE_INPUT;
  GPIO_InitStruct.Pull = GPIO_NOPULL;
  HAL_GPIO_Init(Kill_Switch_DI_GPIO_Port, &GPIO_InitStruct);

  /*Configure GPIO pin : BUF_FB_DI_Pin */
  GPIO_InitStruct.Pin = BUF_FB_DI_Pin;
  GPIO_InitStruct.Mode = GPIO_MODE_INPUT;
  GPIO_InitStruct.Pull = GPIO_NOPULL;
  HAL_GPIO_Init(BUF_FB_DI_GPIO_Port, &GPIO_InitStruct);

  /*Configure GPIO pins : PD4 PD5 PD6 */
  GPIO_InitStruct.Pin = GPIO_PIN_4|GPIO_PIN_5|GPIO_PIN_6;
  GPIO_InitStruct.Mode = GPIO_MODE_ANALOG;
  GPIO_InitStruct.Pull = GPIO_NOPULL;
  HAL_GPIO_Init(GPIOD, &GPIO_InitStruct);

  /*Configure GPIO pin : FLASH_HOLD_DO_Pin */
  GPIO_InitStruct.Pin = FLASH_HOLD_DO_Pin;
  GPIO_InitStruct.Mode = GPIO_MODE_OUTPUT_PP;
  GPIO_InitStruct.Pull = GPIO_NOPULL;
  GPIO_InitStruct.Speed = GPIO_SPEED_FREQ_LOW;
  HAL_GPIO_Init(FLASH_HOLD_DO_GPIO_Port, &GPIO_InitStruct);

  /*Configure GPIO pin : PB7 */
  GPIO_InitStruct.Pin = GPIO_PIN_7;
  GPIO_InitStruct.Mode = GPIO_MODE_ANALOG;
  GPIO_InitStruct.Pull = GPIO_NOPULL;
  HAL_GPIO_Init(GPIOB, &GPIO_InitStruct);

}

/* USER CODE BEGIN 4 */
/**
  * @brief  Retargets the C library printf function to the USART.
  * @param  None
  * @retval None
  */
#if MEASURE_CPU_LOAD || JUDGE_FUNCTION_DELAY

static void USER_DWT_Init(void)
{
    CoreDebug->DEMCR |= CoreDebug_DEMCR_TRCENA_Msk; // Enable access to DWT
    DWT->CTRL |= DWT_CTRL_CYCCNTENA_Msk;            // Enable CYCCNT register
    DWT->CYCCNT = 0;                                // Reset the CYCCNT counter
    return;
}
#endif
/* USER CODE END 4 */

void Error_Handler(void)
{
  __disable_irq();
  while (1)
  {
  }
}
